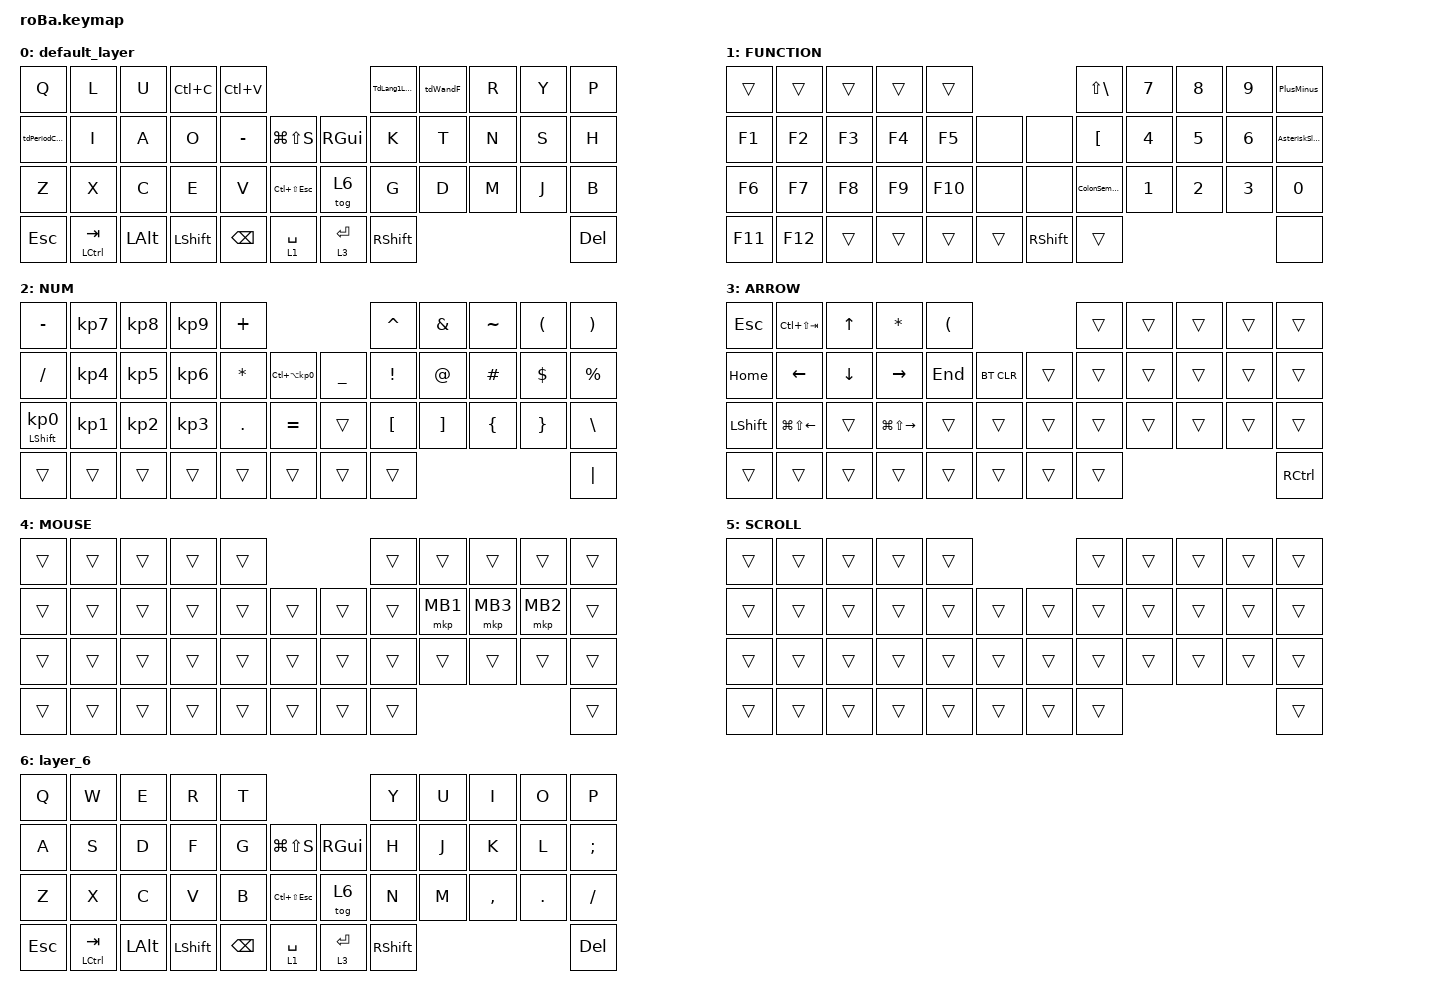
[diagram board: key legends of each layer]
#include <behaviors.dtsi>
#include <dt-bindings/zmk/bt.h>
#include <dt-bindings/zmk/keys.h>
#include <dt-bindings/zmk/pointing.h>

#define MOUSE 4
#define SCROLL 5

&mt {
    flavor = "balanced";
    quick-tap-ms = <0>;
};

/ {
    				combos {
		compatible = "zmk,combos";
		Alt_tab {
			timeout-ms = <50>;
			key-positions = <12 13>;
			layers = <0 1 2 3 4 5>;
			bindings = <&kp LA(TAB)>;
		};
		Ctrl_Z {
			timeout-ms = <50>;
			key-positions = <12 11>;
			bindings = <&kp LC(Z)>;
		};
		Ctrl_P {
			timeout-ms = <50>;
			key-positions = <14 13>;
			bindings = <&kp LC(P)>;
		};
		Ctrl_S {
			timeout-ms = <50>;
			key-positions = <10 14>;
			bindings = <&kp LC(S)>;
		};
		Lang2 {
			timeout-ms = <50>;
			key-positions = <19 20>;
			bindings = <&kp LANG2>;
		};
		Lang1 {
			timeout-ms = <50>;
			key-positions = <18 19>;
			bindings = <&kp LANG1>;
		};
	};

    macros {
        to_layer_0: to_layer_0 {
            compatible = "zmk,behavior-macro-one-param";
            #binding-cells = <1>;
            bindings = <&to 0 &macro_param_1to1 &kp MACRO_PLACEHOLDER>;
            label = "TO_LAYER_0";
        };
    };

    behaviors {
lt_to_layer_0: lt_to_layer_0 {
            compatible = "zmk,behavior-hold-tap";
            label = "LAYER_TAP_TO_0";
            bindings = <&mo>, <&to_layer_0>;
            #binding-cells = <2>;
            tapping-term-ms = <200>;
        };

        tdPeriodComma: tdPeriodComma {
            compatible = "zmk,behavior-tap-dance";
            label = "TDPERIODCOMMA";
            #binding-cells = <0>;
            bindings = <&kp COMMA>, <&kp PERIOD>;
        };

        tdWandF: tdWandF {
            compatible = "zmk,behavior-tap-dance";
            label = "TDWANDF";
            #binding-cells = <0>;
            bindings = <&kp W>, <&kp F>;

            tapping-term-ms = <150>;
        };

        PlusMinus: PlusMinus {
            compatible = "zmk,behavior-tap-dance";
            label = "PLUSMINUS";
            #binding-cells = <0>;
            bindings = <&kp LS(SEMI)>, <&kp MINUS>;

            tapping-term-ms = <200>;
        };

        AsteriskSlash: AsteriskSlash {
            compatible = "zmk,behavior-tap-dance";
            label = "ASTERISKSLASH";
            #binding-cells = <0>;
            tapping-term-ms = <200>;
            bindings = <&kp LS(SINGLE_QUOTE)>, <&kp SLASH>;
        };

        ColonSemicolon: ColonSemicolon {
            compatible = "zmk,behavior-tap-dance";
            label = "COLONSEMICOLON";
            #binding-cells = <0>;
            tapping-term-ms = <200>;
            bindings = <&kp APOS>, <&kp SEMI>;
        };

        TdLang1Lang2: TdLang1Lang2 {
            compatible = "zmk,behavior-tap-dance";
            label = "TDLANG1LANG2";
            #binding-cells = <0>;
            bindings = <&kp LANGUAGE_1>, <&kp LANG2>;
        };
    };

    keymap {
        compatible = "zmk,keymap";

        default_layer {
            bindings = <
&kp Q
&kp L
&kp U
&kp LC(C)
&kp LC(V)
&TdLang1Lang2
&tdWandF
&kp R
&kp Y
&kp P
&tdPeriodComma
&kp I
&kp A
&kp O
&kp MINUS
&kp LG(LS(S))
&kp RGUI
&kp K
&kp T
&kp N
&kp S
&kp H
&kp Z
&kp X
&kp C
&kp E
&kp V
&kp LC(LS(ESCAPE))
&tog 6
&kp G
&kp D
&kp M
&kp J
&kp B
&kp ESC
&mt LCTRL TAB
&kp LEFT_ALT
&kp LEFT_SHIFT
&kp BACKSPACE
&lt 1 SPACE
&lt 3 ENTER
&kp RIGHT_SHIFT
&kp DEL
            >;

            sensor-bindings = <&inc_dec_kp PG_UP PAGE_DOWN>;
        };

        FUNCTION {
            bindings = <
&trans
&trans
&trans
&trans
&trans
&kp LS(BACKSLASH)
&kp NUMBER_7
&kp NUMBER_8
&kp N9
&PlusMinus
&kp F1
&kp F2
&kp F3
&kp F4
&kp F5
&none
&none
&kp LEFT_BRACKET
&kp NUMBER_4
&kp NUMBER_5
&kp NUMBER_6
&AsteriskSlash
&kp F6
&kp F7
&kp F8
&kp F9
&kp F10
&none
&none
&ColonSemicolon
&kp NUMBER_1
&kp NUMBER_2
&kp NUMBER_3
&kp N0
&kp F11
&kp F12
&trans
&trans
&trans
&trans
&kp RIGHT_SHIFT
&trans
&none
            >;
        };

        NUM {
            bindings = <
&kp MINUS                   &kp KP_NUMBER_7  &kp KP_NUMBER_8  &kp KP_NUMBER_9  &kp PLUS                                                   &kp CARET         &kp AMPERSAND      &kp TILDE       &kp LEFT_PARENTHESIS  &kp RIGHT_PARENTHESIS
&kp SLASH                   &kp KP_NUMBER_4  &kp KP_NUMBER_5  &kp KP_NUMBER_6  &kp ASTERISK  &kp LC(LA(KP_NUMBER_0))      &kp UNDERSCORE  &kp EXCLAMATION   &kp AT_SIGN        &kp HASH        &kp DOLLAR            &kp PERCENT
&mt LEFT_SHIFT KP_NUMBER_0  &kp KP_NUMBER_1  &kp KP_NUMBER_2  &kp KP_NUMBER_3  &kp PERIOD    &kp EQUAL                    &trans          &kp LEFT_BRACKET  &kp RIGHT_BRACKET  &kp LEFT_BRACE  &kp RIGHT_BRACE       &kp BACKSLASH
&trans                      &trans           &trans           &trans           &trans        &trans                       &trans          &trans                                                                     &kp PIPE
            >;
        };

        ARROW {
            bindings = <
&kp ESCAPE      &kp LC(LS(TAB))         &kp UP_ARROW    &kp ASTERISK             &kp LEFT_PARENTHESIS                      &trans  &trans  &trans  &trans  &trans
&kp HOME        &kp LEFT_ARROW          &kp DOWN_ARROW  &kp RIGHT_ARROW          &kp END               &bt BT_CLR  &trans  &trans  &trans  &trans  &trans  &trans
&kp LEFT_SHIFT  &kp LG(LS(LEFT_ARROW))  &trans          &kp LG(LS(RIGHT_ARROW))  &trans                &trans      &trans  &trans  &trans  &trans  &trans  &trans
&trans          &trans                  &trans          &trans                   &trans                &trans      &trans  &trans                          &kp RCTRL
            >;

            sensor-bindings = <&inc_dec_kp LC(PAGE_UP) LC(PAGE_DOWN)>;
        };

        MOUSE {
            bindings = <
&trans  &trans  &trans  &trans  &trans                      &trans  &trans    &trans    &trans    &trans
&trans  &trans  &trans  &trans  &trans  &trans      &trans  &trans  &mkp MB1  &mkp MB3  &mkp MB2  &trans
&trans  &trans  &trans  &trans  &trans  &trans      &trans  &trans  &trans    &trans    &trans    &trans
&trans  &trans  &trans  &trans  &trans  &trans      &trans  &trans                                &trans
            >;
        };

        SCROLL {
            bindings = <
&trans  &trans  &trans  &trans  &trans                      &trans  &trans  &trans  &trans  &trans
&trans  &trans  &trans  &trans  &trans  &trans      &trans  &trans  &trans  &trans  &trans  &trans
&trans  &trans  &trans  &trans  &trans  &trans      &trans  &trans  &trans  &trans  &trans  &trans
&trans  &trans  &trans  &trans  &trans  &trans      &trans  &trans                          &trans
            >;
        };

        layer_6 {
            bindings = <
&kp Q  &kp W  &kp E  &kp R  &kp T                                    &kp Y  &kp U  &kp I  &kp O      &kp P
&kp A  &kp S  &kp D  &kp F  &kp G  &kp LG(LS(S))          &kp RGUI  &kp H  &kp J  &kp K  &kp L      &kp SEMI
&kp Z  &kp X  &kp C  &kp V  &kp B  &kp LC(LS(ESCAPE))     &tog 6    &kp N  &kp M  &kp COMMA  &kp DOT  &kp SLASH
&kp ESC  &mt LCTRL TAB  &kp LEFT_ALT  &kp LEFT_SHIFT  &kp BACKSPACE  &lt 1 SPACE  &lt 3 ENTER  &kp RIGHT_SHIFT  &kp DEL
            >;
        };
    };
};
